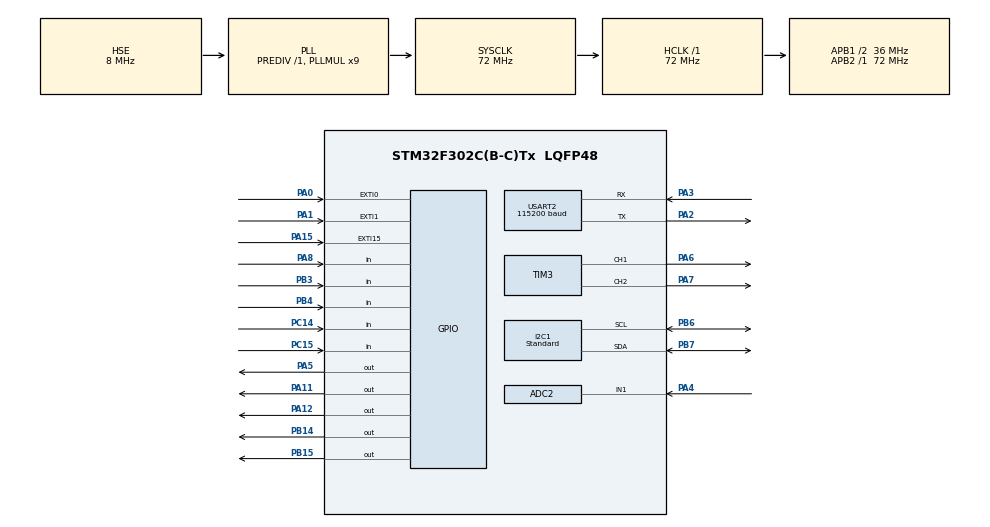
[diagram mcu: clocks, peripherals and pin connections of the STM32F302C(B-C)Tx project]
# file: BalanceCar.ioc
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ADC2.Channel-0\#ChannelRegularConversion=ADC_CHANNEL_VREFINT
ADC2.Channel-1\#ChannelRegularConversion=ADC_CHANNEL_1
ADC2.ContinuousConvMode=ENABLE
ADC2.NbrOfConversion=2
ADC2.NbrOfConversionFlag=1
ADC2.Offset-0\#ChannelRegularConversion=0
ADC2.Offset-1\#ChannelRegularConversion=0
ADC2.OffsetNumber-0\#ChannelRegularConversion=ADC_OFFSET_NONE
ADC2.OffsetNumber-1\#ChannelRegularConversion=ADC_OFFSET_NONE
ADC2.Rank-0\#ChannelRegularConversion=1
ADC2.Rank-1\#ChannelRegularConversion=2
ADC2.SamplingTime-0\#ChannelRegularConversion=ADC_SAMPLETIME_181CYCLES_5
ADC2.SamplingTime-1\#ChannelRegularConversion=ADC_SAMPLETIME_601CYCLES_5
ADC2.SamplingTimeOPAMP-1\#ChannelRegularConversion=ADC_SAMPLETIME_61CYCLES_5
Dma.ADC2.2.Direction=DMA_PERIPH_TO_MEMORY
Dma.ADC2.2.Instance=DMA2_Channel1
Dma.ADC2.2.MemDataAlignment=DMA_MDATAALIGN_HALFWORD
Dma.ADC2.2.MemInc=DMA_MINC_ENABLE
Dma.ADC2.2.Mode=DMA_NORMAL
Dma.ADC2.2.PeriphDataAlignment=DMA_PDATAALIGN_HALFWORD
Dma.ADC2.2.PeriphInc=DMA_PINC_DISABLE
Dma.ADC2.2.Priority=DMA_PRIORITY_LOW
Dma.Request0=USART2_RX
Dma.Request1=USART2_TX
Dma.Request2=ADC2
Dma.USART2_RX.0.Direction=DMA_PERIPH_TO_MEMORY
Dma.USART2_RX.0.Instance=DMA1_Channel6
Dma.USART2_RX.0.MemDataAlignment=DMA_MDATAALIGN_BYTE
Dma.USART2_RX.0.MemInc=DMA_MINC_ENABLE
Dma.USART2_RX.0.Mode=DMA_NORMAL
Dma.USART2_RX.0.PeriphDataAlignment=DMA_PDATAALIGN_BYTE
Dma.USART2_RX.0.PeriphInc=DMA_PINC_DISABLE
Dma.USART2_RX.0.Priority=DMA_PRIORITY_LOW
Dma.USART2_TX.1.Direction=DMA_MEMORY_TO_PERIPH
Dma.USART2_TX.1.Instance=DMA1_Channel7
Dma.USART2_TX.1.MemDataAlignment=DMA_MDATAALIGN_BYTE
Dma.USART2_TX.1.MemInc=DMA_MINC_ENABLE
Dma.USART2_TX.1.Mode=DMA_NORMAL
Dma.USART2_TX.1.PeriphDataAlignment=DMA_PDATAALIGN_BYTE
Dma.USART2_TX.1.PeriphInc=DMA_PINC_DISABLE
Dma.USART2_TX.1.Priority=DMA_PRIORITY_LOW
I2C1.I2C_Speed_Mode=I2C_Standard
I2C1.Timing=0x00201D2B
Mcu.Family=STM32F3
Mcu.Name=STM32F302C(B-C)Tx
Mcu.Package=LQFP48
NVIC.DMA1_Channel6_IRQn=true\:0\:0\:false\:false\:true\:false\:true\:true
NVIC.DMA1_Channel7_IRQn=true\:0\:0\:false\:false\:true\:false\:true\:true
NVIC.DMA2_Channel1_IRQn=true\:0\:0\:false\:false\:true\:false\:true\:true
NVIC.EXTI0_IRQn=true\:0\:0\:false\:false\:true\:true\:true\:true
NVIC.EXTI15_10_IRQn=true\:0\:0\:false\:false\:true\:true\:true\:true
NVIC.EXTI1_IRQn=true\:0\:0\:false\:false\:true\:true\:true\:true
NVIC.I2C1_EV_IRQn=true\:0\:0\:false\:false\:true\:true\:true\:true
NVIC.PriorityGroup=NVIC_PRIORITYGROUP_4
NVIC.USART2_IRQn=true\:0\:0\:false\:false\:true\:false\:true\:true
PA0.GPIO_ModeDefaultEXTI=GPIO_MODE_IT_RISING_FALLING
PA0.Signal=GPXTI0
PA1.GPIO_ModeDefaultEXTI=GPIO_MODE_IT_RISING_FALLING
PA1.Signal=GPXTI1
PA11.Signal=GPIO_Output
PA12.Signal=GPIO_Output
PA13.Mode=Serial_Wire
PA13.Signal=SYS_JTMS-SWDIO
PA14.Mode=Serial_Wire
PA14.Signal=SYS_JTCK-SWCLK
PA15.Signal=GPXTI15
PA2.Mode=Asynchronous
PA2.Signal=USART2_TX
PA3.Mode=Asynchronous
PA3.Signal=USART2_RX
PA4.Mode=IN1-Single-Ended
PA4.Signal=ADC2_IN1
PA5.Signal=GPIO_Output
PA6.Signal=S_TIM3_CH1
PA7.Signal=S_TIM3_CH2
PA8.GPIO_PuPd=GPIO_PULLDOWN
PA8.Signal=GPIO_Input
PB14.Signal=GPIO_Output
PB15.Signal=GPIO_Output
PB3.Signal=GPIO_Input
PB4.Signal=GPIO_Input
PB6.Mode=I2C
PB6.Signal=I2C1_SCL
PB7.Mode=I2C
PB7.Signal=I2C1_SDA
PC14-OSC32_IN.Signal=GPIO_Input
PC15-OSC32_OUT.Signal=GPIO_Input
PF0-OSC_IN.Mode=HSE-External-Oscillator
PF0-OSC_IN.Signal=RCC_OSC_IN
PF1-OSC_OUT.Mode=HSE-External-Oscillator
PF1-OSC_OUT.Signal=RCC_OSC_OUT
ProjectManager.HeapSize=0x200
ProjectManager.StackSize=0x400
ProjectManager.TargetToolchain=CMake
RCC.AHBFreq_Value=72000000
RCC.APB1CLKDivider=RCC_HCLK_DIV2
RCC.APB1Freq_Value=36000000
RCC.APB1TimFreq_Value=72000000
RCC.APB2Freq_Value=72000000
RCC.APB2TimFreq_Value=72000000
RCC.CortexFreq_Value=72000000
RCC.HCLKFreq_Value=72000000
RCC.HSE_VALUE=8000000
RCC.HSI_VALUE=8000000
RCC.LSE_VALUE=32768
RCC.PLLMUL=RCC_PLL_MUL9
RCC.PLLSourceVirtual=RCC_PLLSOURCE_HSE
RCC.SYSCLKFreq_VALUE=72000000
RCC.SYSCLKSourceVirtual=RCC_SYSCLKSOURCE_PLLCLK
RCC.USBFreq_Value=72000000
SH.S_TIM3_CH1.0=TIM3_CH1,PWM Generation1 CH1
SH.S_TIM3_CH2.0=TIM3_CH2,PWM Generation2 CH2
TIM3.Channel-PWM\ Generation1\ CH1=TIM_CHANNEL_1
TIM3.Channel-PWM\ Generation2\ CH2=TIM_CHANNEL_2
USART2.BaudRate=115200
USART2.VirtualMode-Asynchronous=VM_ASYNC
VP_ADC2_Vref_Input.Mode=IN-Vrefint
VP_TIM3_VS_ClockSourceINT.Mode=Internal
board=custom

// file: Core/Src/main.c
/* USER CODE BEGIN Header */
/**
  ******************************************************************************
  * @file           : main.c
  * @brief          : Main program body
  ******************************************************************************
  * @attention
  *
  * Copyright (c) 2026 STMicroelectronics.
  * All rights reserved.
  *
  * This software is licensed under terms that can be found in the LICENSE file
  * in the root directory of this software component.
  * If no LICENSE file comes with this software, it is provided AS-IS.
  *
  ******************************************************************************
  */
/* USER CODE END Header */
#include "main.h"
#include "adc.h"
#include "dma.h"
#include "i2c.h"
#include "tim.h"
#include "usart.h"
#include "gpio.h"

/* USER CODE BEGIN Includes */
#include "fpu.h"
#include "app_main.h"
/* USER CODE END Includes */

void SystemClock_Config(void);

int main(void)
{

  /* USER CODE BEGIN 1 */
  EnableFPU();
  /* USER CODE END 1 */

  /* MCU Configuration--------------------------------------------------------*/

  /* Reset of all peripherals, Initializes the Flash interface and the Systick. */
  HAL_Init();

  /* Configure the system clock */
  SystemClock_Config();

  /* Initialize all configured peripherals */
  MX_GPIO_Init();
  MX_DMA_Init();
  MX_ADC2_Init();
  MX_TIM3_Init();
  MX_USART2_UART_Init();
  MX_I2C1_Init();
  /* USER CODE BEGIN 2 */
  app_main();
  /* USER CODE END 2 */

  /* Infinite loop */
  /* USER CODE BEGIN WHILE */
  while (1)
  {
    loop();
    /* USER CODE END WHILE */

  }
}

void SystemClock_Config(void)
{
  RCC_OscInitTypeDef RCC_OscInitStruct = {0};
  RCC_ClkInitTypeDef RCC_ClkInitStruct = {0};
  RCC_PeriphCLKInitTypeDef PeriphClkInit = {0};

  /** Initializes the RCC Oscillators according to the specified parameters
  * in the RCC_OscInitTypeDef structure.
  */
  RCC_OscInitStruct.OscillatorType = RCC_OSCILLATORTYPE_HSI|RCC_OSCILLATORTYPE_HSE;
  RCC_OscInitStruct.HSEState = RCC_HSE_ON;
  RCC_OscInitStruct.HSEPredivValue = RCC_HSE_PREDIV_DIV1;
  RCC_OscInitStruct.HSIState = RCC_HSI_ON;
  RCC_OscInitStruct.HSICalibrationValue = RCC_HSICALIBRATION_DEFAULT;
  RCC_OscInitStruct.PLL.PLLState = RCC_PLL_ON;
  RCC_OscInitStruct.PLL.PLLSource = RCC_PLLSOURCE_HSE;
  RCC_OscInitStruct.PLL.PLLMUL = RCC_PLL_MUL9;
  if (HAL_RCC_OscConfig(&RCC_OscInitStruct) != HAL_OK)
  {
    Error_Handler();
  }

  /** Initializes the CPU, AHB and APB buses clocks
  */
  RCC_ClkInitStruct.ClockType = RCC_CLOCKTYPE_HCLK|RCC_CLOCKTYPE_SYSCLK
                              |RCC_CLOCKTYPE_PCLK1|RCC_CLOCKTYPE_PCLK2;
  RCC_ClkInitStruct.SYSCLKSource = RCC_SYSCLKSOURCE_PLLCLK;
  RCC_ClkInitStruct.AHBCLKDivider = RCC_SYSCLK_DIV1;
  RCC_ClkInitStruct.APB1CLKDivider = RCC_HCLK_DIV2;
  RCC_ClkInitStruct.APB2CLKDivider = RCC_HCLK_DIV1;

  if (HAL_RCC_ClockConfig(&RCC_ClkInitStruct, FLASH_LATENCY_2) != HAL_OK)
  {
    Error_Handler();
  }
  PeriphClkInit.PeriphClockSelection = RCC_PERIPHCLK_USART2|RCC_PERIPHCLK_I2C1
                              |RCC_PERIPHCLK_ADC12;
  PeriphClkInit.Usart2ClockSelection = RCC_USART2CLKSOURCE_PCLK1;
  PeriphClkInit.Adc12ClockSelection = RCC_ADC12PLLCLK_DIV1;
  PeriphClkInit.I2c1ClockSelection = RCC_I2C1CLKSOURCE_HSI;
  if (HAL_RCCEx_PeriphCLKConfig(&PeriphClkInit) != HAL_OK)
  {
    Error_Handler();
  }
}

void Error_Handler(void)
{
  __disable_irq();
  while (1)
  {
  }
}
